# ATtiny167 register map
Vendor: Atmel; File version: 1.0
CPU: other r0p0, little endian, no MPU, no FPU, 4 interrupt priority bits
Registers are 8-bit, read-write, reset 0x0 unless marked. A register's access mark holds for its fields unless they carry their own. Offsets are from the block's base; [hi:lo] are bit positions; 'fields as' and 'values as' point back to an identical list.

## BOOT_LOAD — Bootloader
Base 0x00800057
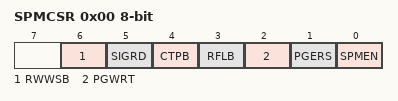
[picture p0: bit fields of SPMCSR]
0x00 SPMCSR — Store Program Memory Control Register
  [6] RWWSB — Read While Write Section Busy
  [5] SIGRD — Signature Row Read
  [4] CTPB — Clear Temporary Page Buffer
  [3] RFLB — Read Fuse and Lock Bits
  [2] PGWRT — Page Write
  [1] PGERS — Page Erase
  [0] SPMEN — Store Program Memory Enable

## CPU — CPU Registers
Base 0x00800032
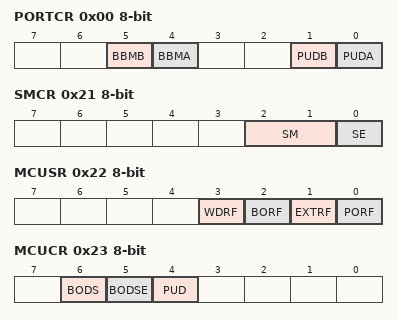
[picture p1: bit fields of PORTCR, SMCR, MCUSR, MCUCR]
0x00 PORTCR — Port Control Register
  [5] BBMB, [4] BBMA, [1] PUDB, [0] PUDA
0x0C GPIOR0 — General purpose register 0
0x18 GPIOR1 — General Purpose register 1
0x19 GPIOR2 — General Purpose IO register 2
0x1F DWDR — DebugWire data register (write-only for debugger)
0x21 SMCR — Sleep Mode Control Register
  [2:1] SM — Sleep Mode Select Bits
    0=IDLE; 1=ADC (ADC Noise Reduction (If Available)); 2=PDOWN (Power-down); 3=PSAVE (Power-save)
  [0] SE — Sleep Enable
0x22 MCUSR — MCU Status register
  [3] WDRF — Watchdog Reset Flag
  [2] BORF — Brown-out Reset Flag
  [1] EXTRF — External Reset Flag
  [0] PORF — Power-On Reset Flag
0x23 MCUCR — MCU Control Register
  [6] BODS — BOD Sleep
  [5] BODSE — BOD Sleep Enable
  [4] PUD — Pull-up Disable
0x2B SP 16-bit (reset mask 0xFF) — Stack Pointer Bytes
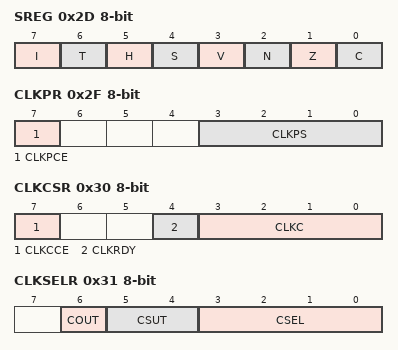
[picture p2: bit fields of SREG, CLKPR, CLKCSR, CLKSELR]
0x2D SREG — Status Register
  [7] I — Global Interrupt Enable
  [6] T — Bit Copy Storage
  [5] H — Half Carry Flag
  [4] S — Sign Bit
  [3] V — Two's Complement Overflow Flag
  [2] N — Negative Flag
  [1] Z — Zero Flag
  [0] C — Carry Flag
0x2F CLKPR — Clock Prescale Register (read-only for debugger)
  [7] CLKPCE — Clock Prescaler Change Enable
  [3:0] CLKPS — Clock Prescaler Select Bits
    0=1; 1=2; 2=4; 3=8; 4=16; 5=32; 6=64; 7=128; 8=256
0x30 CLKCSR — Clock Control & Status Register
  [7] CLKCCE — Clock Control Change Enable
  [4] CLKRDY — Clock Ready Flag
  [3:0] CLKC — Clock Control bits
    0=NO_COMMAND; 1=DISABLE_CLOCK_SOURCE; 2=ENABLE_CLOCK_SOURCE; 3=REQUEST_FOR_CLOCK_AVAILABILITY; 4=CLOCK_SOURCE_SWITCH; 5=RECOVERY_SYSTEM_CLOCK_SOURCE_CODE; 6=ENABLE_WATCHDOG_IN_AUTOMATIC_RELOAD_MODE; 7=CKOUT_COMMAND; 8=FROM_0X08_UP_TO_0X0F_NO_COMMAND
0x31 CLKSELR — Clock Selection Register
  [6] COUT — Clock Out - CKOUT fuse substitution
  [5:4] CSUT — Clock Start-up Time bit 1 - SUT1 fuse substitution
  [3:0] CSEL — Clock Source Select bit 3 - CKSEL3 fuse substitution
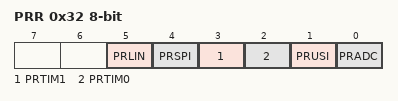
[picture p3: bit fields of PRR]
0x32 PRR — Power Reduction Register
  [5] PRLIN — Power Reduction LINUART
  [4] PRSPI — Power Reduction SPI
  [3] PRTIM1 — Power Reduction Timer/Counter1
  [2] PRTIM0 — Power Reduction Timer/Counter0
  [1] PRUSI — Power Reduction USI
  [0] PRADC — Power Reduction ADC
0x34 OSCCAL — Oscillator Calibration Register (read-only for debugger)
  [7:0] OSCCAL — Oscillator Calibration

## CURRENT_SOURCE
Base 0x00800077
0x00 AMISCR — Analog Miscellaneous Control Register (Shared with AD_CONVERTER IO_MODULE)
  [0] ISRCEN — Current Source Enable

## EEPROM
Base 0x0080003F
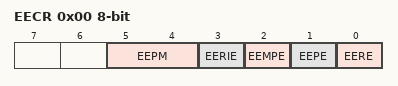
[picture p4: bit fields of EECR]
0x00 EECR — EEPROM Control Register
  [5:4] EEPM — EEPROM Programming Mode Bits
    0=ERASE_AND_WRITE_IN_ONE_OPERATION; 1=ERASE_ONLY; 2=WRITE_ONLY
  [3] EERIE — EEPROM Ready Interrupt Enable
  [2] EEMPE — EEPROM Master Write Enable
  [1] EEPE — EEPROM Write Enable
  [0] EERE — EEPROM Read Enable
0x01 EEDR — EEPROM Data Register
0x02 EEAR 16-bit (reset mask 0xFF) — EEPROM Address Register Bytes

## EXINT — External Interrupts
Base 0x0080003B
0x00 PCIFR — Pin Change Interrupt Flag Register (read-only for debugger)
  [1:0] PCIF — Pin Change Interrupt Flags
0x01 EIFR — External Interrupt Flag Register (read-only for debugger)
  [1:0] INTF — External Interrupt Flags
0x02 EIMSK — External Interrupt Mask Register
  [1:0] INT — External Interrupt Request 1 Enable
0x2D PCICR — Pin Change Interrupt Control Register
  [1:0] PCIE — Pin Change Interrupt Enable on any PCINT14..8 pin
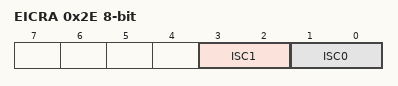
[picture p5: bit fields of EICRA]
0x2E EICRA — External Interrupt Control Register
  [3:2] ISC1 — External Interrupt Sense Control 1 Bits
    0=LOW_LEVEL_OF_INTX; 1=ANY_LOGICAL_CHANGE_IN_INTX; 2=FALLING_EDGE_OF_INTX; 3=RISING_EDGE_OF_INTX
  [1:0] ISC0 — External Interrupt Sense Control 0 Bits
    values as ISC1
0x30 PCMSK0 — Pin Change Mask Register 0
  [7:0] PCINT — Pin Change Enable Masks
0x31 PCMSK1 — Pin Change Mask Register 1
  [7:0] PCINT — Pin Change Enable Masks
